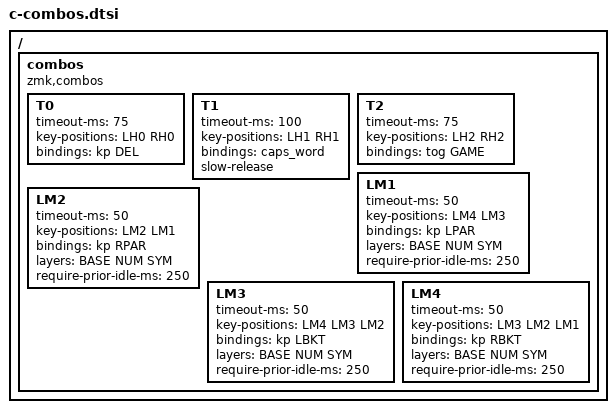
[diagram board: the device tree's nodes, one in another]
/ {
    combos {
        compatible = "zmk,combos";
        T0 {
            timeout-ms = <75>;
            key-positions = <LH0 RH0>;
            bindings = <&kp DEL>;
        };
        T1 {
            timeout-ms = <100>;
            key-positions = <LH1 RH1>;
            bindings = <&caps_word>;
            slow-release;
        };
        T2 {
            timeout-ms = <75>;
            key-positions = <LH2 RH2>;
            bindings = <&tog GAME>;
        };
        LM1 {
            timeout-ms = <50>;
            key-positions = <LM4 LM3>;
            bindings = <&kp LPAR>;
            layers = <BASE NUM SYM>;
            require-prior-idle-ms = <250>;
        };
        LM2 {
            timeout-ms = <50>;
            key-positions = <LM2 LM1>;
            bindings = <&kp RPAR>;
            layers = <BASE NUM SYM>;
            require-prior-idle-ms = <250>;
        };
        LM3 {
            timeout-ms = <50>;
            key-positions = <LM4 LM3 LM2>;
            bindings = <&kp LBKT>;
            layers = <BASE NUM SYM>;
            require-prior-idle-ms = <250>;
        };
        LM4 {
            timeout-ms = <50>;
            key-positions = <LM3 LM2 LM1>;
            bindings = <&kp RBKT>;
            layers = <BASE NUM SYM>;
            require-prior-idle-ms = <250>;
        };
    };
};
